# STM32G544xx register map
File version: 1.0
Registers are 32-bit, read-write, reset 0x0 unless marked. A register's access mark holds for its fields unless they carry their own. Offsets are from the block's base; [hi:lo] are bit positions; {n}, {i} and the like mark numbered series.

## GTZC1_MPCBB1
Base 0x40032C00
Same registers: GTZC1_MPCBB2 0x40033000
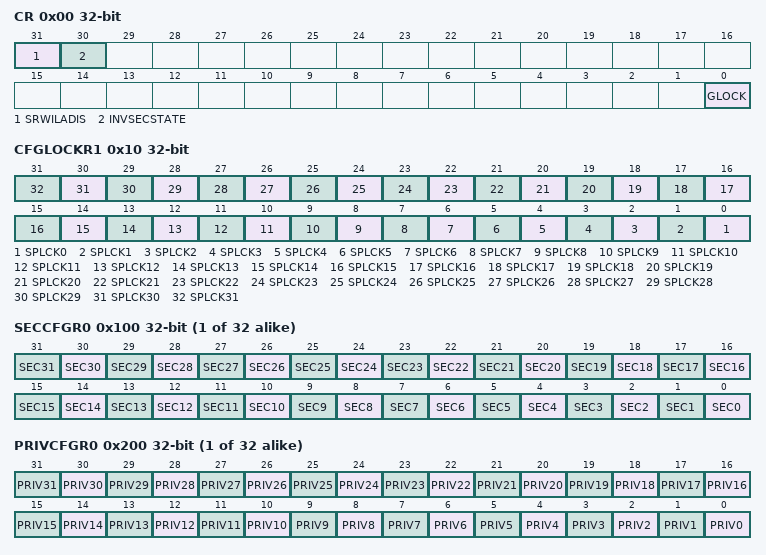
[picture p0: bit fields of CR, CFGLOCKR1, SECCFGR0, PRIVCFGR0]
0x00 CR — MPCBBx control register
  [31] SRWILADIS, [30] INVSECSTATE, [0] GLOCK
0x10 CFGLOCKR1 — MPCBBx lock register
  [n] SPLCK{n} (n=0..31)
{0x100+4i} SECCFGR{i} (i=0..31) — MPCBBx security configuration registers
  [n] SEC{n} (n=0..31)
{0x200+4i} PRIVCFGR{i} (i=0..31) — MPCBBx privilege configuration registers
  [n] PRIV{n} (n=0..31)

## ADC12_COMMON
Base 0x42020300
0x00 CSR ro — ADC common status register
0x08 CCR — ADC common control register
0x0C CDR ro — ADC common regular data register for dual mode
0x10 CDR2 ro — ADC common regular data register for dual mode

## DAC1 — Digital to Analog Converter (DAC)
Base 0x42021400
Same registers: DAC2 0x42021800, DAC5 0x42022400, DAC6 0x42022800, DAC7 0x42022C00, DAC8 0x42023000, DAC9 0x42023400, DAC10 0x42023800
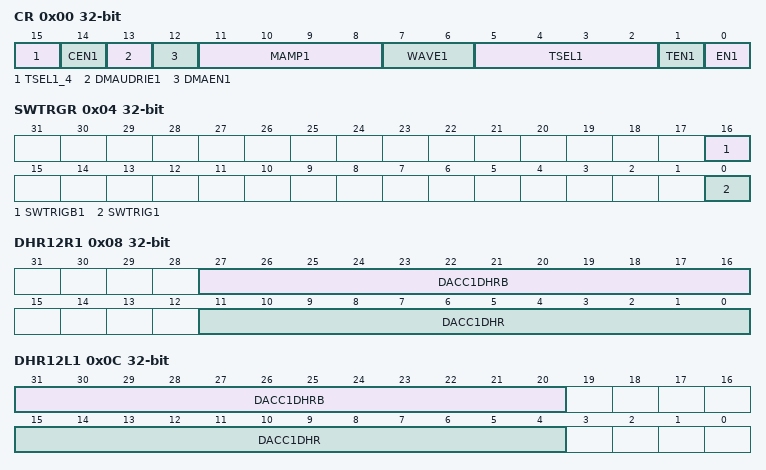
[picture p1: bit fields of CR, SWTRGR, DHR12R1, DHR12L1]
0x00 CR — DAC control register
  [15] TSEL1_4
  [14] CEN1
  [13] DMAUDRIE1
  [12] DMAEN1 — DAC channel1 DMA enable
  [11:8] MAMP1
  [7:6] WAVE1
  [5:2] TSEL1
  [1] TEN1 — DAC channel1 trigger enable
  [0] EN1 — DAC channel1 enable
0x04 SWTRGR — DAC software trigger register
  [16] SWTRIGB1
  [0] SWTRIG1 — DAC channel1 software trigger
0x08 DHR12R1 — DAC channel1 12-bit right-aligned data holding register
  [27:16] DACC1DHRB, [11:0] DACC1DHR
0x0C DHR12L1 — DAC channel1 12-bit left aligned data holding register
  [31:20] DACC1DHRB, [15:4] DACC1DHR
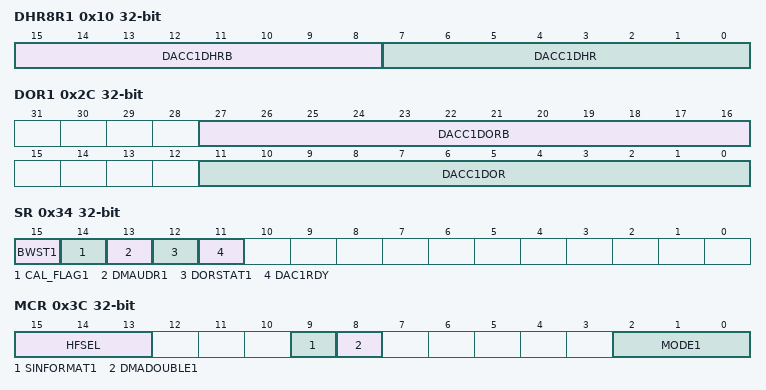
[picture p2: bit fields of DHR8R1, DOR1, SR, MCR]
0x10 DHR8R1 — DAC channel1 8-bit right aligned data holding register
  [15:8] DACC1DHRB, [7:0] DACC1DHR
0x2C DOR1 ro — DAC channel1 data output register
  [27:16] DACC1DORB — DAC channel1 data output
  [11:0] DACC1DOR — DAC channel1 data output
0x34 SR — DAC status register
  [15] BWST1
  [14] CAL_FLAG1
  [13] DMAUDR1
  [12] DORSTAT1
  [11] DAC1RDY — DAC channel1 ready status bit
0x38 CCR — DAC calibration control register
  [4:0] OTRIM1
0x3C MCR — DAC mode control register
  [15:13] HFSEL
  [9] SINFORMAT1
  [8] DMADOUBLE1
  [2:0] MODE1 — DAC channel1 mode
0x40 SHSR1 — DAC channel1 sample and hold sample time register
  [9:0] TSAMPLE1
0x48 SHHR — DAC sample and hold time register
  [9:0] THOLD1
0x4C SHRR — DAC sample and hold refresh time register
  [7:0] TREFRESH1
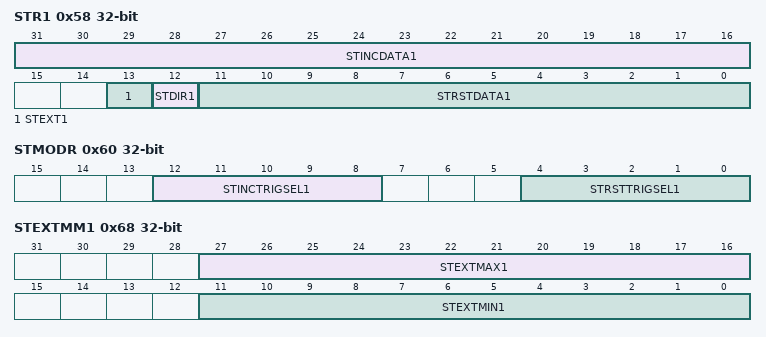
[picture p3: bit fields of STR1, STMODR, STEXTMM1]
0x58 STR1 — DAC channel1 sawtooth register
  [31:16] STINCDATA1, [13] STEXT1, [12] STDIR1, [11:0] STRSTDATA1
0x60 STMODR — DAC sawtooth mode register
  [12:8] STINCTRIGSEL1, [4:0] STRSTTRIGSEL1
0x64 STEXTRST — DAC extended sawtooth reset control register
  [15:0] STEXTRSTDATA1
0x68 STEXTMM1 — DAC extended sawtooth minimum and maximum value register
  [27:16] STEXTMAX1, [11:0] STEXTMIN1
0x3EC OR — DAC option register
  [1:0] OP — Option bits

## SBS — System configuration, boot and security (SBS)
Base 0x44000400
0x10 HDPLCR — SBS temporal isolation control register
  [7:0] INCR_HDPL — increment HDPL value
0x14 HDPLSR ro — SBS temporal isolation status register
  [7:0] HDPL — temporal isolation level
0x18 NEXTHDPLCR — SBS next HDPL control register
  [1:0] NEXTHDPL
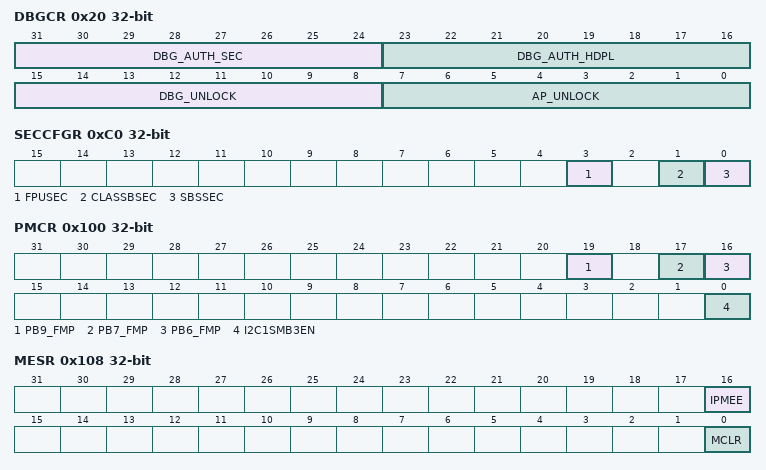
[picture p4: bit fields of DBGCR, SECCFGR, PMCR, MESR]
0x20 DBGCR — SBS debug control register
  [31:24] DBG_AUTH_SEC
  [23:16] DBG_AUTH_HDPL
  [15:8] DBG_UNLOCK
  [7:0] AP_UNLOCK — access port unlock
0x24 DBGLOCKR — SBS debug lock register
  [7:0] DBGCFG_LOCK — debug configuration lock
0x28 DBGCR2 — SBS debug control register 2
  [7:0] SEC_AP_UNLOCK
0x34 RSSCMDR — SBS RSS command register
  [15:0] RSSCMD — RSS command
0xA0 EPOCHSELCR — SBS EPOCH selection control register
  [1:0] EPOCH_SEL
0xC0 SECCFGR — SBS security mode configuration control register
  [3] FPUSEC — FPU security enable
  [1] CLASSBSEC — ClassB security enable
  [0] SBSSEC
0x100 PMCR — SBS product mode and configuration register
  [19] PB9_FMP
  [17] PB7_FMP
  [16] PB6_FMP
  [0] I2C1SMB3EN — SMBUS 3.0 on I2C1 enable
0x104 FPUIMR — SBS FPU interrupt mask register
  [5:0] FPU_IE — FPU interrupt enable
0x108 MESR — SBS memory erase status register
  [16] IPMEE — ICACHE erase status
  [0] MCLR — device memories erase status
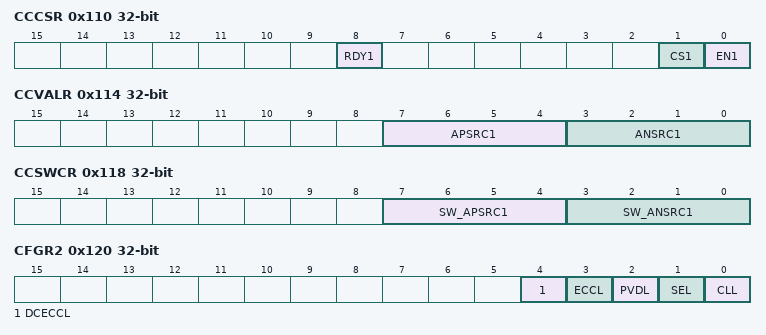
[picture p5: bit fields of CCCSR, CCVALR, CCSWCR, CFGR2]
0x110 CCCSR — SBS compensation cell for I/Os control and status register
  [8] RDY1, [1] CS1, [0] EN1
0x114 CCVALR ro — SBS compensation cell for I/Os value register
  [7:4] APSRC1, [3:0] ANSRC1
0x118 CCSWCR — SBS compensation cell for I/Os software code register
  [7:4] SW_APSRC1, [3:0] SW_ANSRC1
0x120 CFGR2 — SBS Class B register
  [4] DCECCL — DCACHE ECC lock
  [3] ECCL — ECC lock
  [2] PVDL — PVD lock
  [1] SEL — SRAM ECC error lock
  [0] CLL — core lockup lock
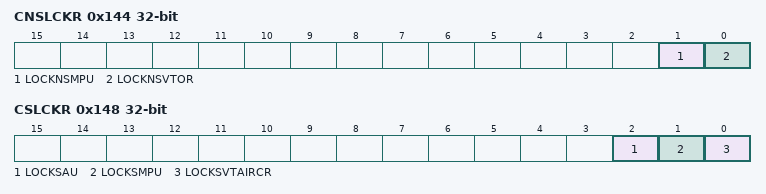
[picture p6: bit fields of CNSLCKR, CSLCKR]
0x144 CNSLCKR — SBS CPU nonsecure lock register
  [1] LOCKNSMPU — nonsecure MPU register lock
  [0] LOCKNSVTOR — VTOR_NS register lock
0x148 CSLCKR — SBS CPU secure lock register
  [2] LOCKSAU — SAU registers lock
  [1] LOCKSMPU — secure MPU registers lock
  [0] LOCKSVTAIRCR
0x14C ECCNMIR — SBS ECC NMI mask register
  [0] ECCNMI_MASK_EN
0x170 SWAPLOCKR — SBS debug control register 2
  [7:0] SWAP_LOCK
0x174 FBMODER — SBS debug control register 2
  [7:0] FB_MODE — Flash bank mode selection
